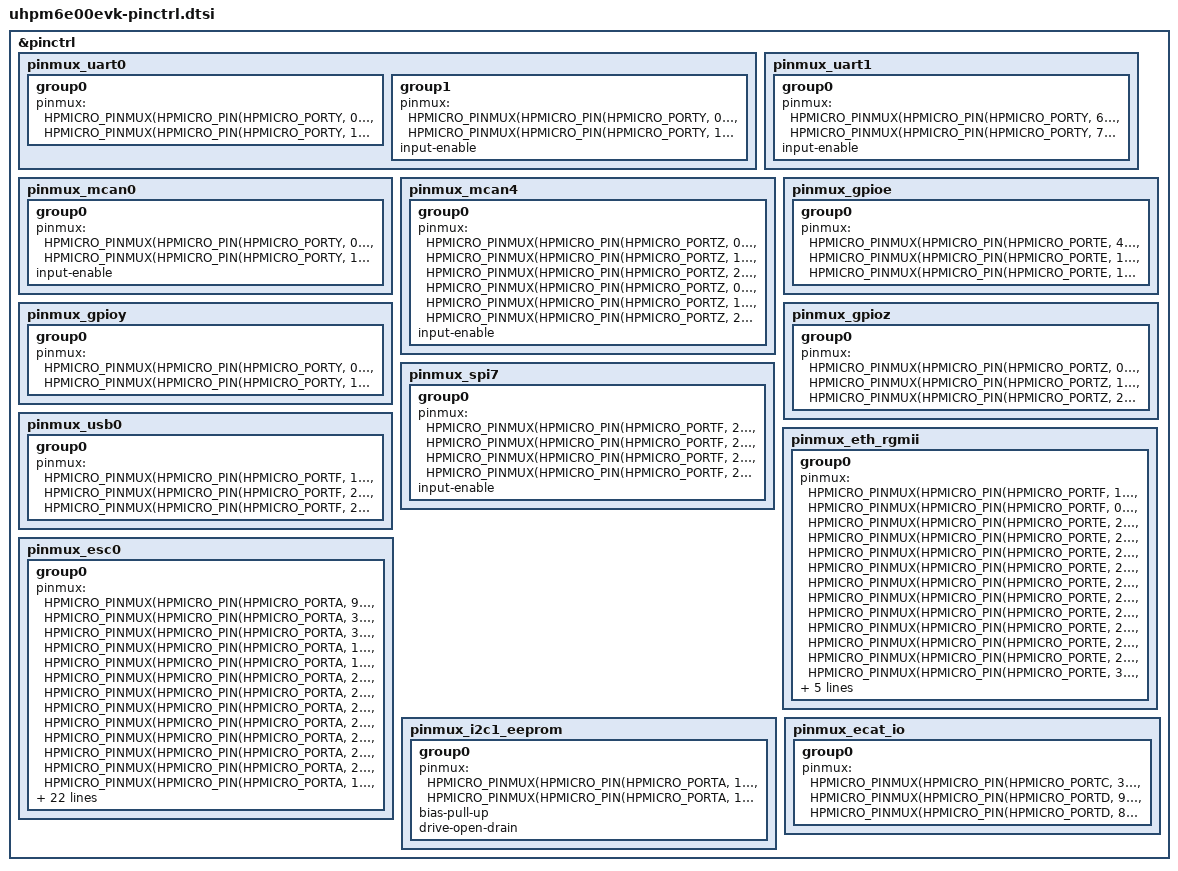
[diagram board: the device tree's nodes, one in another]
/*
 * Copyright 2025 HPMicro
 * SPDX-License-Identifier: Apache-2.0
 */

#include "dt-bindings/pinctrl/hpmicro-pinctrl-common.h"

&pinctrl {
	pinmux_uart0: pinmux_uart0 {
		group0 {
			// PIOC ALT=3: 把控制权交给 IOC
			pinmux = <HPMICRO_PINMUX(HPMICRO_PIN(HPMICRO_PORTY, 0), IOC_TYPE_PIOC, 0, 3)>,
					 <HPMICRO_PINMUX(HPMICRO_PIN(HPMICRO_PORTY, 1), IOC_TYPE_PIOC, 0, 3)>;
		};
		group1 {
			// IOC ALT=2: UART0 TXD / RXD
			pinmux = <HPMICRO_PINMUX(HPMICRO_PIN(HPMICRO_PORTY, 0), IOC_TYPE_IOC, 0, 2)>,
					 <HPMICRO_PINMUX(HPMICRO_PIN(HPMICRO_PORTY, 1), IOC_TYPE_IOC, 0, 2)>;
			input-enable;
		};
	};

	pinmux_uart1: pinmux_uart1 {
		group0 {
			pinmux = <HPMICRO_PINMUX(HPMICRO_PIN(HPMICRO_PORTY, 6), IOC_TYPE_IOC, 0, 2)>,
					 <HPMICRO_PINMUX(HPMICRO_PIN(HPMICRO_PORTY, 7), IOC_TYPE_IOC, 0, 2)>;
			input-enable;
		};
	};

	pinmux_mcan0: pinmux_mcan0 {
		group0 {
			pinmux = <HPMICRO_PINMUX(HPMICRO_PIN(HPMICRO_PORTY, 0), IOC_TYPE_IOC, 0, 7)>,
					 <HPMICRO_PINMUX(HPMICRO_PIN(HPMICRO_PORTY, 1), IOC_TYPE_IOC, 0, 7)>;
			input-enable;
		};
	};

	pinmux_mcan4: pinmux_mcan4 {
		group0 {
			pinmux = <HPMICRO_PINMUX(HPMICRO_PIN(HPMICRO_PORTZ, 0), IOC_TYPE_IOC, 0, 7)>,
					 <HPMICRO_PINMUX(HPMICRO_PIN(HPMICRO_PORTZ, 1), IOC_TYPE_IOC, 0, 7)>,
					 <HPMICRO_PINMUX(HPMICRO_PIN(HPMICRO_PORTZ, 2), IOC_TYPE_IOC, 0, 7)>,
					 <HPMICRO_PINMUX(HPMICRO_PIN(HPMICRO_PORTZ, 0), IOC_TYPE_BIOC, 0, 3)>,
					 <HPMICRO_PINMUX(HPMICRO_PIN(HPMICRO_PORTZ, 1), IOC_TYPE_BIOC, 0, 3)>,
					 <HPMICRO_PINMUX(HPMICRO_PIN(HPMICRO_PORTZ, 2), IOC_TYPE_BIOC, 0, 3)>;
			input-enable;
		};
	};

	pinmux_gpioe: pinmux_gpioe {
		group0 {
			pinmux = <HPMICRO_PINMUX(HPMICRO_PIN(HPMICRO_PORTE, 4), IOC_TYPE_IOC, 0, 0)>,
					 <HPMICRO_PINMUX(HPMICRO_PIN(HPMICRO_PORTE, 14), IOC_TYPE_IOC, 0, 0)>,
					 <HPMICRO_PINMUX(HPMICRO_PIN(HPMICRO_PORTE, 15), IOC_TYPE_IOC, 0, 0)>;
		};
	};

	pinmux_gpioy: pinmux_gpioy {
		group0 {
			pinmux = <HPMICRO_PINMUX(HPMICRO_PIN(HPMICRO_PORTY, 0), IOC_TYPE_IOC, 0, 0)>,
					 <HPMICRO_PINMUX(HPMICRO_PIN(HPMICRO_PORTY, 1), IOC_TYPE_IOC, 0, 0)>;
		};
	};

	pinmux_gpioz: pinmux_gpioz {
		group0 {
			pinmux = <HPMICRO_PINMUX(HPMICRO_PIN(HPMICRO_PORTZ, 0), IOC_TYPE_IOC, 0, 0)>,
					 <HPMICRO_PINMUX(HPMICRO_PIN(HPMICRO_PORTZ, 1), IOC_TYPE_IOC, 0, 0)>,
					 <HPMICRO_PINMUX(HPMICRO_PIN(HPMICRO_PORTZ, 2), IOC_TYPE_IOC, 0, 0)>;
		};
	};

	pinmux_spi7: pinmux_spi7 {
		group0 {
			pinmux = <HPMICRO_PINMUX(HPMICRO_PIN(HPMICRO_PORTF, 27), IOC_TYPE_IOC, 0, 5)>,
					 <HPMICRO_PINMUX(HPMICRO_PIN(HPMICRO_PORTF, 28), IOC_TYPE_IOC, 0, 5)>,
					 <HPMICRO_PINMUX(HPMICRO_PIN(HPMICRO_PORTF, 29), IOC_TYPE_IOC, 0, 5)>,
					 <HPMICRO_PINMUX(HPMICRO_PIN(HPMICRO_PORTF, 26), IOC_TYPE_IOC, 0, 5)>;
			input-enable;
		};
	};

	pinmux_usb0: pinmux_usb0 {
		group0 {
			pinmux = <HPMICRO_PINMUX(HPMICRO_PIN(HPMICRO_PORTF, 19), IOC_TYPE_IOC, 0, 24)>,
					 <HPMICRO_PINMUX(HPMICRO_PIN(HPMICRO_PORTF, 22), IOC_TYPE_IOC, 0, 24)>,
					 <HPMICRO_PINMUX(HPMICRO_PIN(HPMICRO_PORTF, 23), IOC_TYPE_IOC, 0, 24)>;
		};
	};

	pinmux_eth_rgmii: pinmux_eth_rgmii {
		group0 {
			pinmux = <HPMICRO_PINMUX(HPMICRO_PIN(HPMICRO_PORTF, 1), IOC_TYPE_IOC, 0, 18)>,
					 <HPMICRO_PINMUX(HPMICRO_PIN(HPMICRO_PORTF, 0), IOC_TYPE_IOC, 0, 18)>,
					 <HPMICRO_PINMUX(HPMICRO_PIN(HPMICRO_PORTE, 20), IOC_TYPE_IOC, 0, 18)>,
					 <HPMICRO_PINMUX(HPMICRO_PIN(HPMICRO_PORTE, 21), IOC_TYPE_IOC, 0, 18)>,
					 <HPMICRO_PINMUX(HPMICRO_PIN(HPMICRO_PORTE, 22), IOC_TYPE_IOC, 0, 18)>,
					 <HPMICRO_PINMUX(HPMICRO_PIN(HPMICRO_PORTE, 23), IOC_TYPE_IOC, 0, 18)>,
					 <HPMICRO_PINMUX(HPMICRO_PIN(HPMICRO_PORTE, 24), IOC_TYPE_IOC, 0, 18)>,
					 <HPMICRO_PINMUX(HPMICRO_PIN(HPMICRO_PORTE, 25), IOC_TYPE_IOC, 0, 18)>,
					 <HPMICRO_PINMUX(HPMICRO_PIN(HPMICRO_PORTE, 26), IOC_TYPE_IOC, 0, 18)>,
					 <HPMICRO_PINMUX(HPMICRO_PIN(HPMICRO_PORTE, 27), IOC_TYPE_IOC, 0, 18)>,
					 <HPMICRO_PINMUX(HPMICRO_PIN(HPMICRO_PORTE, 28), IOC_TYPE_IOC, 0, 18)>,
					 <HPMICRO_PINMUX(HPMICRO_PIN(HPMICRO_PORTE, 29), IOC_TYPE_IOC, 0, 18)>,
					 <HPMICRO_PINMUX(HPMICRO_PIN(HPMICRO_PORTE, 30), IOC_TYPE_IOC, 0, 18)>,
					 <HPMICRO_PINMUX(HPMICRO_PIN(HPMICRO_PORTE, 31), IOC_TYPE_IOC, 0, 18)>;
			input-schmitt-enable;
			slew-rate = "fast";
			slew-pd = "100M";
			drive-strength = "r011";
		};
	};

	// ESC（EtherCAT）引脚 —— HPM6E00EVK RevA
	// 依据 hpm_sdk/boards/hpm6e00evk/pinmux.c 的 init_esc_pins() 逐条搬入。
	// 除 PE06(EVTO_0)=ALT27 外，其余 ESC 功能均为 ALT11。
	// PA10（PHY 复位）由 dts 的 phy-reset-gpios 走 GPIO 控制，不在此复用。
	pinmux_esc0: pinmux_esc0 {
		group0 {
			pinmux = <HPMICRO_PINMUX(HPMICRO_PIN(HPMICRO_PORTA, 9), IOC_TYPE_IOC, 0, 11)>,
					 <HPMICRO_PINMUX(HPMICRO_PIN(HPMICRO_PORTA, 30), IOC_TYPE_IOC, 0, 11)>,
					 <HPMICRO_PINMUX(HPMICRO_PIN(HPMICRO_PORTA, 31), IOC_TYPE_IOC, 0, 11)>,
					 <HPMICRO_PINMUX(HPMICRO_PIN(HPMICRO_PORTA, 15), IOC_TYPE_IOC, 0, 11)>,
					 <HPMICRO_PINMUX(HPMICRO_PIN(HPMICRO_PORTA, 11), IOC_TYPE_IOC, 0, 11)>,
					 <HPMICRO_PINMUX(HPMICRO_PIN(HPMICRO_PORTA, 24), IOC_TYPE_IOC, 0, 11)>,
					 <HPMICRO_PINMUX(HPMICRO_PIN(HPMICRO_PORTA, 29), IOC_TYPE_IOC, 0, 11)>,
					 <HPMICRO_PINMUX(HPMICRO_PIN(HPMICRO_PORTA, 25), IOC_TYPE_IOC, 0, 11)>,
					 <HPMICRO_PINMUX(HPMICRO_PIN(HPMICRO_PORTA, 26), IOC_TYPE_IOC, 0, 11)>,
					 <HPMICRO_PINMUX(HPMICRO_PIN(HPMICRO_PORTA, 27), IOC_TYPE_IOC, 0, 11)>,
					 <HPMICRO_PINMUX(HPMICRO_PIN(HPMICRO_PORTA, 28), IOC_TYPE_IOC, 0, 11)>,
					 <HPMICRO_PINMUX(HPMICRO_PIN(HPMICRO_PORTA, 21), IOC_TYPE_IOC, 0, 11)>,
					 <HPMICRO_PINMUX(HPMICRO_PIN(HPMICRO_PORTA, 16), IOC_TYPE_IOC, 0, 11)>,
					 <HPMICRO_PINMUX(HPMICRO_PIN(HPMICRO_PORTA, 23), IOC_TYPE_IOC, 0, 11)>,
					 <HPMICRO_PINMUX(HPMICRO_PIN(HPMICRO_PORTA, 17), IOC_TYPE_IOC, 0, 11)>,
					 <HPMICRO_PINMUX(HPMICRO_PIN(HPMICRO_PORTA, 18), IOC_TYPE_IOC, 0, 11)>,
					 <HPMICRO_PINMUX(HPMICRO_PIN(HPMICRO_PORTA, 19), IOC_TYPE_IOC, 0, 11)>,
					 <HPMICRO_PINMUX(HPMICRO_PIN(HPMICRO_PORTA, 20), IOC_TYPE_IOC, 0, 11)>,
					 <HPMICRO_PINMUX(HPMICRO_PIN(HPMICRO_PORTA, 22), IOC_TYPE_IOC, 0, 11)>,
					 <HPMICRO_PINMUX(HPMICRO_PIN(HPMICRO_PORTB, 18), IOC_TYPE_IOC, 0, 11)>,
					 <HPMICRO_PINMUX(HPMICRO_PIN(HPMICRO_PORTB, 23), IOC_TYPE_IOC, 0, 11)>,
					 <HPMICRO_PINMUX(HPMICRO_PIN(HPMICRO_PORTB, 19), IOC_TYPE_IOC, 0, 11)>,
					 <HPMICRO_PINMUX(HPMICRO_PIN(HPMICRO_PORTB, 20), IOC_TYPE_IOC, 0, 11)>,
					 <HPMICRO_PINMUX(HPMICRO_PIN(HPMICRO_PORTB, 21), IOC_TYPE_IOC, 0, 11)>,
					 <HPMICRO_PINMUX(HPMICRO_PIN(HPMICRO_PORTB, 22), IOC_TYPE_IOC, 0, 11)>,
					 <HPMICRO_PINMUX(HPMICRO_PIN(HPMICRO_PORTB, 17), IOC_TYPE_IOC, 0, 11)>,
					 <HPMICRO_PINMUX(HPMICRO_PIN(HPMICRO_PORTB, 12), IOC_TYPE_IOC, 0, 11)>,
					 <HPMICRO_PINMUX(HPMICRO_PIN(HPMICRO_PORTB, 13), IOC_TYPE_IOC, 0, 11)>,
					 <HPMICRO_PINMUX(HPMICRO_PIN(HPMICRO_PORTB, 14), IOC_TYPE_IOC, 0, 11)>,
					 <HPMICRO_PINMUX(HPMICRO_PIN(HPMICRO_PORTB, 15), IOC_TYPE_IOC, 0, 11)>,
					 <HPMICRO_PINMUX(HPMICRO_PIN(HPMICRO_PORTB, 16), IOC_TYPE_IOC, 0, 11)>,
					 <HPMICRO_PINMUX(HPMICRO_PIN(HPMICRO_PORTA, 12), IOC_TYPE_IOC, 0, 11)>,
					 <HPMICRO_PINMUX(HPMICRO_PIN(HPMICRO_PORTA, 13), IOC_TYPE_IOC, 0, 11)>;
			slew-rate = "fast";
			drive-strength = "r011";
		};
	};

	/* ESC EEPROM 的 I2C1（MCU 预烧 CAT24C128 用；ESC 自己读时切回 ESC0_SDA/SCL） */
	pinmux_i2c1_eeprom: pinmux_i2c1_eeprom {
		group0 {
			pinmux = <HPMICRO_PINMUX(HPMICRO_PIN(HPMICRO_PORTA, 12), IOC_TYPE_IOC, 0, 4)>,
					 <HPMICRO_PINMUX(HPMICRO_PIN(HPMICRO_PORTA, 13), IOC_TYPE_IOC, 0, 4)>;
			bias-pull-up;
			drive-open-drain;
		};
	};

	/* EtherCAT 数字 IO：IN1/IN2 是 ESC 的 GPI，OUT1 是 ESC 的 GPO */
	pinmux_ecat_io: pinmux_ecat_io {
		group0 {
			pinmux = <HPMICRO_PINMUX(HPMICRO_PIN(HPMICRO_PORTC, 31), IOC_TYPE_IOC, 0, 10)>,
					 <HPMICRO_PINMUX(HPMICRO_PIN(HPMICRO_PORTD, 9), IOC_TYPE_IOC, 0, 10)>,
					 <HPMICRO_PINMUX(HPMICRO_PIN(HPMICRO_PORTD, 8), IOC_TYPE_IOC, 0, 11)>;
		};
	};
};
